AUTOSAR XML (schema 4-2-2)
package /DemoApplication/SwComponentTypes
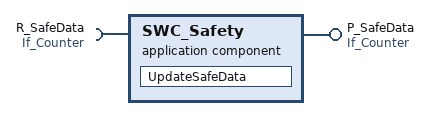
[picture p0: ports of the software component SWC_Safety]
  application sw component type SWC_Safety
    provide port P_SafeData: provided-interface=If_Counter
    require port R_SafeData: required-interface=If_Counter
    behavior IB_SWC_Safety: handle-termination-and-restart=NO-SUPPORT
      data received event SafeDataReceived: start-on-event=UpdateSafeData, data=R_SafeData.CounterValue
      runnable UpdateSafeData: symbol=SWC_Safe_Data_Received
        data-receive-point-by-arguments:
          access SafeDataIn: accessed-variable=R_SafeData.CounterValue
        data-write-access:
          access SafeDataOut: accessed-variable=P_SafeData.CounterValue
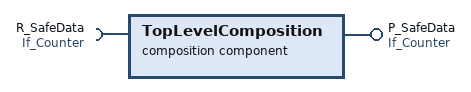
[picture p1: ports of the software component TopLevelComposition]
  composition sw component type TopLevelComposition
    provide port P_SafeData: provided-interface=If_Counter
    require port R_SafeData: required-interface=If_Counter
    component SWC_Safety: type=SWC_Safety
package /DemoApplication/SwcImplementations
  swc implementation Impl_SWC_Safety: programming-language=C, sw-version=1.0.0, vendor-id=1, behavior=IB_SWC_Safety
    code-descriptors:
      code SRC: artifact-descriptors=autosar-engineering-object={short-label=EngObject, category=SWSRC}
    resource consumption Resources
      memory section RTE_START_SEC_APPL_CODE: sw-addrmethod=CODE, symbol=CODE
